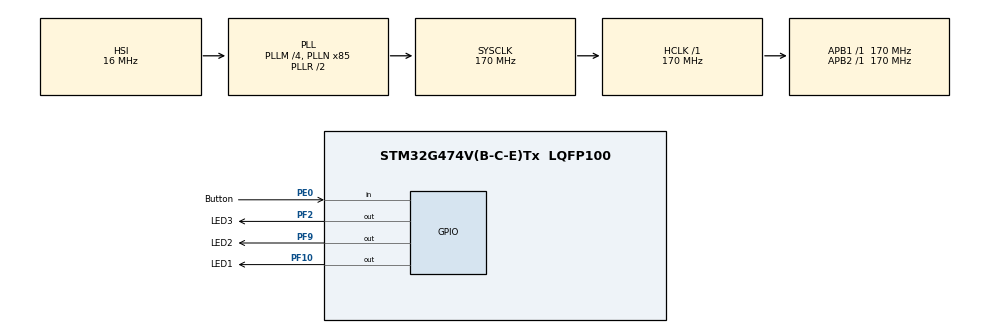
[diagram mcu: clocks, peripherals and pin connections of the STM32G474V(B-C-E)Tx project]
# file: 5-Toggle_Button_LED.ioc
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Mcu.Family=STM32G4
Mcu.Name=STM32G474V(B-C-E)Tx
Mcu.Package=LQFP100
NVIC.PriorityGroup=NVIC_PRIORITYGROUP_4
PE0.GPIO_Label=Button
PE0.GPIO_PuPd=GPIO_PULLUP
PE0.Signal=GPIO_Input
PF0-OSC_IN.Mode=HSE-External-Oscillator
PF0-OSC_IN.Signal=RCC_OSC_IN
PF1-OSC_OUT.Mode=HSE-External-Oscillator
PF1-OSC_OUT.Signal=RCC_OSC_OUT
PF10.GPIO_Label=LED1
PF10.GPIO_Speed=GPIO_SPEED_FREQ_MEDIUM
PF10.PinState=GPIO_PIN_SET
PF10.Signal=GPIO_Output
PF2.GPIO_Label=LED3
PF2.GPIO_Speed=GPIO_SPEED_FREQ_MEDIUM
PF2.PinState=GPIO_PIN_SET
PF2.Signal=GPIO_Output
PF9.GPIO_Label=LED2
PF9.GPIO_Speed=GPIO_SPEED_FREQ_MEDIUM
PF9.PinState=GPIO_PIN_SET
PF9.Signal=GPIO_Output
ProjectManager.HeapSize=0x200
ProjectManager.StackSize=0x400
ProjectManager.TargetToolchain=STM32CubeIDE
RCC.ADC12Freq_Value=170000000
RCC.ADC345Freq_Value=170000000
RCC.AHBFreq_Value=170000000
RCC.APB1Freq_Value=170000000
RCC.APB1TimFreq_Value=170000000
RCC.APB2Freq_Value=170000000
RCC.APB2TimFreq_Value=170000000
RCC.CortexFreq_Value=170000000
RCC.EXTERNAL_CLOCK_VALUE=12288000
RCC.HCLKFreq_Value=170000000
RCC.HSE_VALUE=40000000
RCC.HSI48_VALUE=48000000
RCC.HSI_VALUE=16000000
RCC.LSE_VALUE=32768
RCC.PLLM=RCC_PLLM_DIV4
RCC.PLLN=85
RCC.SYSCLKFreq_VALUE=170000000
RCC.SYSCLKSource=RCC_SYSCLKSOURCE_PLLCLK
RCC.USBFreq_Value=170000000
RCC.VCOOutputFreq_Value=340000000
VP_SYS_VS_DBSignals.Mode=DisableDeadBatterySignals
board=custom

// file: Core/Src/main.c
/* USER CODE BEGIN Header */
/**
  ******************************************************************************
  * @file           : main.c
  * @brief          : Main program body
  ******************************************************************************
  * @attention
  *
  * Copyright (c) 2026 STMicroelectronics.
  * All rights reserved.
  *
  * This software is licensed under terms that can be found in the LICENSE file
  * in the root directory of this software component.
  * If no LICENSE file comes with this software, it is provided AS-IS.
  *
  ******************************************************************************
  */
/* USER CODE END Header */
#include "main.h"

void SystemClock_Config(void);
static void MX_GPIO_Init(void);

int main(void)
{

  /* MCU Configuration--------------------------------------------------------*/

  /* Reset of all peripherals, Initializes the Flash interface and the Systick. */
  HAL_Init();

  /* Configure the system clock */
  SystemClock_Config();

  /* Initialize all configured peripherals */
  MX_GPIO_Init();

  /* Infinite loop */
  /* USER CODE BEGIN WHILE */
  uint8_t last_state = 1;
   while (1)
   {
    /* USER CODE END WHILE */

    /* USER CODE BEGIN 3 */
 	  HAL_GPIO_WritePin(GPIOF, GPIO_PIN_2, RESET);
 	  HAL_GPIO_WritePin(GPIOF, GPIO_PIN_9, RESET);

 	  uint8_t current_state = HAL_GPIO_ReadPin(GPIOE, GPIO_PIN_0);

 	  if (last_state == 1 && current_state == 0)
 	  {
 		  HAL_Delay(50);
 		  if (HAL_GPIO_ReadPin(GPIOE, GPIO_PIN_0) == 0)
 		  {
 			  HAL_GPIO_TogglePin(GPIOF, GPIO_PIN_10);
 		  }
 	  }
 	  last_state = current_state;

   }
  /* USER CODE END 3 */
}

void SystemClock_Config(void)
{
  RCC_OscInitTypeDef RCC_OscInitStruct = {0};
  RCC_ClkInitTypeDef RCC_ClkInitStruct = {0};

  /** Configure the main internal regulator output voltage
  */
  HAL_PWREx_ControlVoltageScaling(PWR_REGULATOR_VOLTAGE_SCALE1_BOOST);

  /** Initializes the RCC Oscillators according to the specified parameters
  * in the RCC_OscInitTypeDef structure.
  */
  RCC_OscInitStruct.OscillatorType = RCC_OSCILLATORTYPE_HSI;
  RCC_OscInitStruct.HSIState = RCC_HSI_ON;
  RCC_OscInitStruct.HSICalibrationValue = RCC_HSICALIBRATION_DEFAULT;
  RCC_OscInitStruct.PLL.PLLState = RCC_PLL_ON;
  RCC_OscInitStruct.PLL.PLLSource = RCC_PLLSOURCE_HSI;
  RCC_OscInitStruct.PLL.PLLM = RCC_PLLM_DIV4;
  RCC_OscInitStruct.PLL.PLLN = 85;
  RCC_OscInitStruct.PLL.PLLP = RCC_PLLP_DIV2;
  RCC_OscInitStruct.PLL.PLLQ = RCC_PLLQ_DIV2;
  RCC_OscInitStruct.PLL.PLLR = RCC_PLLR_DIV2;
  if (HAL_RCC_OscConfig(&RCC_OscInitStruct) != HAL_OK)
  {
    Error_Handler();
  }

  /** Initializes the CPU, AHB and APB buses clocks
  */
  RCC_ClkInitStruct.ClockType = RCC_CLOCKTYPE_HCLK|RCC_CLOCKTYPE_SYSCLK
                              |RCC_CLOCKTYPE_PCLK1|RCC_CLOCKTYPE_PCLK2;
  RCC_ClkInitStruct.SYSCLKSource = RCC_SYSCLKSOURCE_PLLCLK;
  RCC_ClkInitStruct.AHBCLKDivider = RCC_SYSCLK_DIV1;
  RCC_ClkInitStruct.APB1CLKDivider = RCC_HCLK_DIV1;
  RCC_ClkInitStruct.APB2CLKDivider = RCC_HCLK_DIV1;

  if (HAL_RCC_ClockConfig(&RCC_ClkInitStruct, FLASH_LATENCY_4) != HAL_OK)
  {
    Error_Handler();
  }
}

static void MX_GPIO_Init(void)
{
  GPIO_InitTypeDef GPIO_InitStruct = {0};

  /* GPIO Ports Clock Enable */
  __HAL_RCC_GPIOF_CLK_ENABLE();
  __HAL_RCC_GPIOE_CLK_ENABLE();

  /*Configure GPIO pin Output Level */
  HAL_GPIO_WritePin(GPIOF, LED2_Pin|LED1_Pin|LED3_Pin, GPIO_PIN_SET);

  /*Configure GPIO pins : LED2_Pin LED1_Pin LED3_Pin */
  GPIO_InitStruct.Pin = LED2_Pin|LED1_Pin|LED3_Pin;
  GPIO_InitStruct.Mode = GPIO_MODE_OUTPUT_PP;
  GPIO_InitStruct.Pull = GPIO_NOPULL;
  GPIO_InitStruct.Speed = GPIO_SPEED_FREQ_MEDIUM;
  HAL_GPIO_Init(GPIOF, &GPIO_InitStruct);

  /*Configure GPIO pin : Button_Pin */
  GPIO_InitStruct.Pin = Button_Pin;
  GPIO_InitStruct.Mode = GPIO_MODE_INPUT;
  GPIO_InitStruct.Pull = GPIO_PULLUP;
  HAL_GPIO_Init(Button_GPIO_Port, &GPIO_InitStruct);

}

void Error_Handler(void)
{
  __disable_irq();
  while (1)
  {
  }
}
